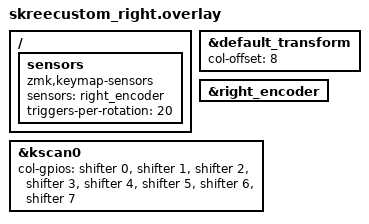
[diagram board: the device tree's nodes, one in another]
#include "skreecustom.dtsi"

 &default_transform {
    col-offset = <8>;
};

&right_encoder {
    status = "okay";
};

/ {
    sensors {
        compatible = "zmk,keymap-sensors";
        sensors = <&right_encoder>;
        triggers-per-rotation = <20>;
    };
};

&kscan0 {
    col-gpios
        = <&shifter 0 GPIO_ACTIVE_HIGH>
        , <&shifter 1 GPIO_ACTIVE_HIGH>
        , <&shifter 2 GPIO_ACTIVE_HIGH>
        , <&shifter 3 GPIO_ACTIVE_HIGH>
        , <&shifter 4 GPIO_ACTIVE_HIGH>
        , <&shifter 5 GPIO_ACTIVE_HIGH>
        , <&shifter 6 GPIO_ACTIVE_HIGH>
        , <&shifter 7 GPIO_ACTIVE_HIGH>
        ;
};
